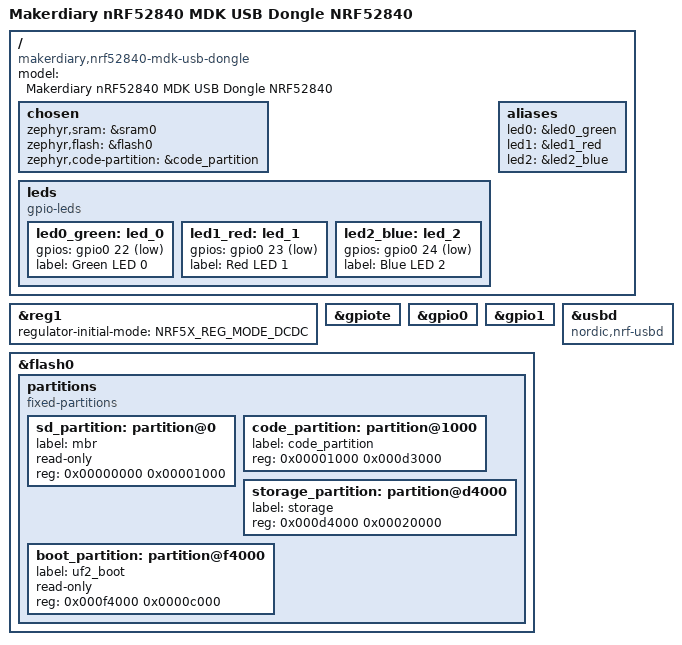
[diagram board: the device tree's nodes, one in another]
/*
 * Copyright (c) 2016-2025 Makerdiary <https://makerdiary.com>
 *
 * SPDX-License-Identifier: Apache-2.0
 *
 * Makerdiary nRF52840-MDK USB dongle.
 * Flash layout matches the UF2 bootloader the dongle ships with
 * (press reset to enter UF2 mass-storage mode):
 *
 *   0x00000000  MBR                 (4 kB)
 *   0x00001000  Application       (844 kB)
 *   0x000d4000  Storage           (128 kB)
 *   0x000f4000  UF2 bootloader    ( 48 kB)
 *
 * See https://wiki.makerdiary.com/nrf52840-mdk-usb-dongle/programming/uf2boot/
 */

/dts-v1/;
#include <nordic/nrf52840_qiaa.dtsi>

/ {
	model = "Makerdiary nRF52840 MDK USB Dongle NRF52840";
	compatible = "makerdiary,nrf52840-mdk-usb-dongle";

	chosen {
		zephyr,sram = &sram0;
		zephyr,flash = &flash0;
		zephyr,code-partition = &code_partition;
	};

	leds {
		compatible = "gpio-leds";
		led0_green: led_0 {
			gpios = <&gpio0 22 GPIO_ACTIVE_LOW>;
			label = "Green LED 0";
		};
		led1_red: led_1 {
			gpios = <&gpio0 23 GPIO_ACTIVE_LOW>;
			label = "Red LED 1";
		};
		led2_blue: led_2 {
			gpios = <&gpio0 24 GPIO_ACTIVE_LOW>;
			label = "Blue LED 2";
		};
	};

	aliases {
		led0 = &led0_green;
		led1 = &led1_red;
		led2 = &led2_blue;
	};
};

&reg1 {
	regulator-initial-mode = <NRF5X_REG_MODE_DCDC>;
};

&gpiote {
	status = "okay";
};

&gpio0 {
	status = "okay";
};

&gpio1 {
	status = "okay";
};

&flash0 {
	partitions {
		compatible = "fixed-partitions";
		#address-cells = <1>;
		#size-cells = <1>;

		sd_partition: partition@0 {
			label = "mbr";
			read-only;
			reg = <0x00000000 0x00001000>;
		};

		code_partition: partition@1000 {
			label = "code_partition";
			reg = <0x00001000 0x000d3000>;
		};

		storage_partition: partition@d4000 {
			label = "storage";
			reg = <0x000d4000 0x00020000>;
		};

		boot_partition: partition@f4000 {
			label = "uf2_boot";
			read-only;
			reg = <0x000f4000 0x0000c000>;
		};
	};
};

zephyr_udc0: &usbd {
	compatible = "nordic,nrf-usbd";
	status = "okay";
};
